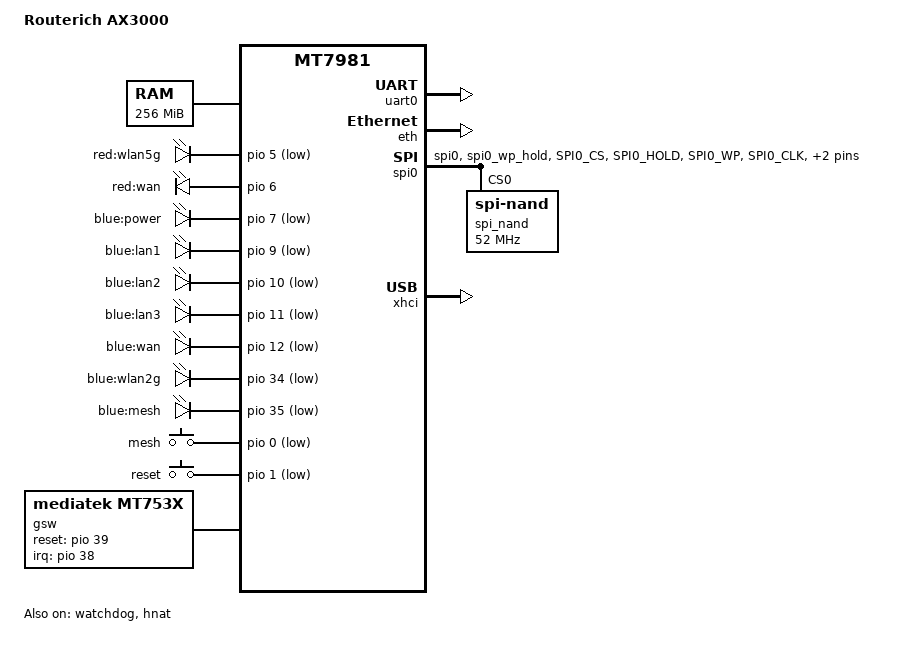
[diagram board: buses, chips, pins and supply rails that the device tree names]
/dts-v1/;
#include "mt7981.dtsi"

/ {
	model = "Routerich AX3000";
	compatible = "routerich,ax3000", "mediatek,mt7981";

	aliases {
		led-boot = &led_power_blue;
		led-failsafe = &led_power_blue;
		led-running = &led_power_blue;
		led-upgrade = &led_power_blue;
	};

	chosen {
		bootargs = "console=ttyS0,115200n1 loglevel=8 \
			    earlycon=uart8250,mmio32,0x11002000";
	};

	memory {
		reg = <0 0x40000000 0 0x10000000>;
	};

	gpio-leds {
		compatible = "gpio-leds";

		led-0 {
			label = "red:wlan5g";
			gpios = <&pio 5 GPIO_ACTIVE_LOW>;
		};

		led-1 {
			label = "red:wan";
			gpios = <&pio 6 GPIO_ACTIVE_HIGH>;
		};

		led_power_blue: led-2 {
			label = "blue:power";
			gpios = <&pio 7 GPIO_ACTIVE_LOW>;
		};

		led-3 {
			label = "blue:lan1";
			gpios = <&pio 9 GPIO_ACTIVE_LOW>;
		};

		led-4 {
			label = "blue:lan2";
			gpios = <&pio 10 GPIO_ACTIVE_LOW>;
		};

		led-5 {
			label = "blue:lan3";
			gpios = <&pio 11 GPIO_ACTIVE_LOW>;
		};

		led-6 {
			label = "blue:wan";
			gpios = <&pio 12 GPIO_ACTIVE_LOW>;
		};

		led-7 {
			label = "blue:wlan2g";
			gpios = <&pio 34 GPIO_ACTIVE_LOW>;
		};

		led-8 {
			label = "blue:mesh";
			gpios = <&pio 35 GPIO_ACTIVE_LOW>;
		};
	};

	gpio-keys {
		compatible = "gpio-keys";

		button-mesh {
			label = "mesh";
			linux,code = <BTN_0>;
			gpios = <&pio 0 GPIO_ACTIVE_LOW>;
		};

		button-reset {
			label = "reset";
			linux,code = <KEY_RESTART>;
			gpios = <&pio 1 GPIO_ACTIVE_LOW>;
		};
	};

	gsw: gsw@0 {
		compatible = "mediatek,mt753x";
		mediatek,ethsys = <&ethsys>;
		#address-cells = <1>;
		#size-cells = <0>;
	};

	nmbm_spim_nand {
		compatible = "generic,nmbm";

		#address-cells = <1>;
		#size-cells = <1>;

		lower-mtd-device = <&spi_nand>;
		forced-create;

		partitions {
			compatible = "fixed-partitions";
			#address-cells = <1>;
			#size-cells = <1>;

			partition@0_all {
				label = "spi0.0";
				reg = <0x0 0x8000000>;
				read-only;
			};

			partition@0 {
				label = "BL2";
				reg = <0x0 0x100000>;
				read-only;
			};

			partition@100000 {
				label = "u-boot-env";
				reg = <0x100000 0x80000>;
			};

			partition@180000 {
				label = "Factory";
				reg = <0x180000 0x200000>;
				read-only;
			};

			partition@380000 {
				label = "FIP";
				reg = <0x380000 0x200000>;
				read-only;
			};

			partition@580000 {
				label = "ubi";
				reg = <0x580000 0x4000000>;
			};

			partition@4580000 {
				label = "firmware_backup";
				reg = <0x4580000 0x2000000>;
				read-only;
			};

			partition@6580000 {
				label = "zrsave";
				reg = <0x6580000 0x100000>;
				read-only;
			};

			partition@6680000 {
				label = "config2";
				reg = <0x6680000 0x100000>;
				read-only;
			};
		};
	};
};

&uart0 {
	status = "okay";
};

&watchdog {
	status = "okay";
};

&eth {
	status = "okay";

	gmac0: mac@0 {
		compatible = "mediatek,eth-mac";
		reg = <0>;
		phy-mode = "2500base-x";

		fixed-link {
			speed = <2500>;
			full-duplex;
			pause;
		};
	};

	gmac1: mac@1 {
		compatible = "mediatek,eth-mac";
		reg = <1>;
		phy-mode = "2500base-x";

		fixed-link {
			speed = <2500>;
			full-duplex;
			pause;
		};
	};

	mdio: mdio-bus {
		#address-cells = <1>;
		#size-cells = <0>;
	};
};

&gsw {
	mediatek,mdio = <&mdio>;
	mediatek,mdio_master_pinmux = <0>;
	reset-gpios = <&pio 39 0>;
	interrupt-parent = <&pio>;
	interrupts = <38 IRQ_TYPE_LEVEL_HIGH>;
	status = "okay";

	port5: port@5 {
		compatible = "mediatek,mt753x-port";
		reg = <5>;
		phy-mode = "sgmii";

		fixed-link {
			speed = <2500>;
			full-duplex;
		};
	};

	port6: port@6 {
		compatible = "mediatek,mt753x-port";
		mediatek,ssc-on;
		reg = <6>;
		phy-mode = "sgmii";

		fixed-link {
			speed = <2500>;
			full-duplex;
		};
	};
};

&hnat {
	mtketh-wan = "eth1";
	mtketh-lan = "eth0";
	mtketh-max-gmac = <2>;

	status = "okay";
};

&spi0 {
	pinctrl-names = "default";
	pinctrl-0 = <&spi0_flash_pins>;
	status = "okay";

	spi_nand: spi_nand@0 {
		#address-cells = <1>;
		#size-cells = <1>;
		compatible = "spi-nand";
		reg = <0>;

		spi-max-frequency = <52000000>;
		spi-tx-bus-width = <4>;
		spi-rx-bus-width = <4>;

		spi-cal-enable;
		spi-cal-mode = "read-data";
		spi-cal-datalen = <7>;
		spi-cal-data = /bits/ 8 <0x53 0x50 0x49 0x4E 0x41 0x4E 0x44>;
		spi-cal-addrlen = <5>;
		spi-cal-addr = /bits/ 32 <0x0 0x0 0x0 0x0 0x0>;
	};
};

&pio {
	spi0_flash_pins: spi0-pins {
		mux {
			function = "spi";
			groups = "spi0", "spi0_wp_hold";
		};

		conf-pu {
			pins = "SPI0_CS", "SPI0_HOLD", "SPI0_WP";
			drive-strength = <MTK_DRIVE_8mA>;
			bias-pull-up = <MTK_PUPD_SET_R1R0_11>;
		};

		conf-pd {
			pins = "SPI0_CLK", "SPI0_MOSI", "SPI0_MISO";
			drive-strength = <MTK_DRIVE_8mA>;
			bias-pull-down = <MTK_PUPD_SET_R1R0_11>;
		};
	};
};

&xhci {
	mediatek,u3p-dis-msk = <0x0>;
	status = "okay";
};
